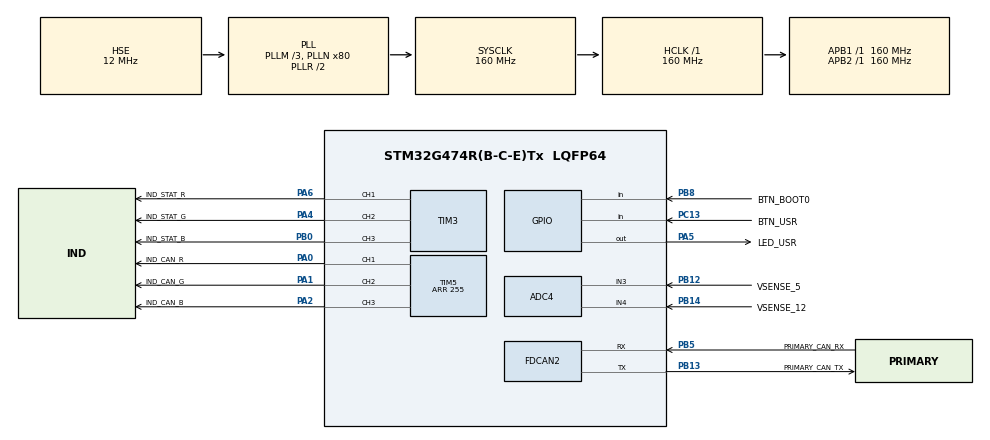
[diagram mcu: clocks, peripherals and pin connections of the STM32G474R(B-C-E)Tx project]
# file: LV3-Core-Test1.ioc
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ADC4.Channel-1\#ChannelRegularConversion=ADC_CHANNEL_3
ADC4.NbrOfConversionFlag=1
ADC4.OffsetNumber-1\#ChannelRegularConversion=ADC_OFFSET_NONE
ADC4.Rank-1\#ChannelRegularConversion=1
ADC4.SamplingTime-1\#ChannelRegularConversion=ADC_SAMPLETIME_2CYCLES_5
FDCAN2.CalculateBaudRateNominal=250000
FDCAN2.CalculateTimeBitNominal=4000
FDCAN2.CalculateTimeQuantumNominal=250.0
FDCAN2.NominalPrescaler=40
FDCAN2.NominalTimeSeg1=13
FDCAN2.NominalTimeSeg2=2
Mcu.Family=STM32G4
Mcu.Name=STM32G474R(B-C-E)Tx
Mcu.Package=LQFP64
NVIC.FDCAN2_IT0_IRQn=true\:0\:0\:false\:false\:true\:true\:true\:true
NVIC.FDCAN2_IT1_IRQn=true\:0\:0\:false\:false\:true\:true\:true\:true
NVIC.PriorityGroup=NVIC_PRIORITYGROUP_4
PA0.GPIO_Label=IND_CAN_R
PA0.Signal=S_TIM5_CH1
PA1.GPIO_Label=IND_CAN_G
PA1.Signal=S_TIM5_CH2
PA11.Signal=USB_DM
PA12.Signal=USB_DP
PA13.Mode=Trace_Asynchronous_SW
PA13.Signal=SYS_JTMS-SWDIO
PA14.Mode=Trace_Asynchronous_SW
PA14.Signal=SYS_JTCK-SWCLK
PA2.GPIO_Label=IND_CAN_B
PA2.Signal=S_TIM5_CH3
PA4.GPIO_Label=IND_STAT_G
PA4.Signal=S_TIM3_CH2
PA5.GPIO_Label=LED_USR
PA5.Signal=GPIO_Output
PA6.GPIO_Label=IND_STAT_R
PA6.Signal=S_TIM3_CH1
PA8.GPIO_Label=AUX_CAN_RX
PA8.Signal=FDCAN3_RX
PB0.GPIO_Label=IND_STAT_B
PB0.Signal=S_TIM3_CH3
PB12.GPIO_Label=VSENSE_5
PB12.Mode=IN3-Single-Ended
PB12.Signal=ADC4_IN3
PB13.GPIO_Label=PRIMARY_CAN_TX
PB13.Mode=FDCAN_Activate
PB13.Signal=FDCAN2_TX
PB14.GPIO_Label=VSENSE_12
PB14.Mode=IN4-Single-Ended
PB14.Signal=ADC4_IN4
PB3.Mode=Trace_Asynchronous_SW
PB3.Signal=SYS_JTDO-SWO
PB4.GPIO_Label=AUX_CAN_TX
PB4.Signal=FDCAN3_TX
PB5.GPIO_Label=PRIMARY_CAN_RX
PB5.Mode=FDCAN_Activate
PB5.Signal=FDCAN2_RX
PB8-BOOT0.GPIO_Label=BTN_BOOT0
PB8-BOOT0.Signal=GPIO_Input
PC13.GPIO_Label=BTN_USR
PC13.Signal=GPIO_Input
PF0-OSC_IN.Mode=HSE-External-Oscillator
PF0-OSC_IN.Signal=RCC_OSC_IN
PF1-OSC_OUT.Mode=HSE-External-Oscillator
PF1-OSC_OUT.Signal=RCC_OSC_OUT
ProjectManager.HeapSize=0x200
ProjectManager.StackSize=0x400
ProjectManager.TargetToolchain=CMake
RCC.ADC12Freq_Value=160000000
RCC.ADC345Freq_Value=160000000
RCC.AHBFreq_Value=160000000
RCC.APB1Freq_Value=160000000
RCC.APB1TimFreq_Value=160000000
RCC.APB2Freq_Value=160000000
RCC.APB2TimFreq_Value=160000000
RCC.CK48CLockSelection=RCC_USBCLKSOURCE_HSI48
RCC.CortexFreq_Value=160000000
RCC.EXTERNAL_CLOCK_VALUE=12288000
RCC.HCLKFreq_Value=160000000
RCC.HSE_VALUE=12000000
RCC.HSI48_VALUE=48000000
RCC.HSI_VALUE=16000000
RCC.LSE_VALUE=32768
RCC.PLLM=RCC_PLLM_DIV3
RCC.PLLN=80
RCC.PLLQ=RCC_PLLQ_DIV4
RCC.PLLSourceVirtual=RCC_PLLSOURCE_HSE
RCC.SYSCLKFreq_VALUE=160000000
RCC.SYSCLKSource=RCC_SYSCLKSOURCE_PLLCLK
RCC.USBFreq_Value=48000000
RCC.VCOOutputFreq_Value=320000000
SH.S_TIM3_CH1.0=TIM3_CH1,PWM Generation1 CH1
SH.S_TIM3_CH2.0=TIM3_CH2,PWM Generation2 CH2
SH.S_TIM3_CH3.0=TIM3_CH3,PWM Generation3 CH3
SH.S_TIM5_CH1.0=TIM5_CH1,PWM Generation1 CH1
SH.S_TIM5_CH2.0=TIM5_CH2,PWM Generation2 CH2
SH.S_TIM5_CH3.0=TIM5_CH3,PWM Generation3 CH3
TIM3.Channel-PWM\ Generation1\ CH1=TIM_CHANNEL_1
TIM3.Channel-PWM\ Generation2\ CH2=TIM_CHANNEL_2
TIM3.Channel-PWM\ Generation3\ CH3=TIM_CHANNEL_3
TIM5.Channel-PWM\ Generation1\ CH1=TIM_CHANNEL_1
TIM5.Channel-PWM\ Generation2\ CH2=TIM_CHANNEL_2
TIM5.Channel-PWM\ Generation3\ CH3=TIM_CHANNEL_3
TIM5.PeriodNoDither=255
VP_SYS_VS_DBSignals.Mode=DisableDeadBatterySignals
VP_TIM3_VS_ClockSourceINT.Mode=Internal
VP_TIM4_VS_ClockSourceINT.Mode=Internal
board=custom

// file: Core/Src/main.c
/* USER CODE BEGIN Header */
/**
 ******************************************************************************
 * @file           : main.c
 * @brief          : Main program body
 ******************************************************************************
 * @attention
 *
 * Copyright (c) 2026 STMicroelectronics.
 * All rights reserved.
 *
 * This software is licensed under terms that can be found in the LICENSE file
 * in the root directory of this software component.
 * If no LICENSE file comes with this software, it is provided AS-IS.
 *
 ******************************************************************************
 */
/* USER CODE END Header */
#include "main.h"

/* USER CODE BEGIN Includes */

#include "LV3_CAN.h"
#include "stm32g4xx_hal_fdcan.h"

/* USER CODE END Includes */

ADC_HandleTypeDef hadc4;

FDCAN_HandleTypeDef hfdcan2;

TIM_HandleTypeDef htim3;
TIM_HandleTypeDef htim4;
TIM_HandleTypeDef htim5;

void SystemClock_Config(void);
static void MX_GPIO_Init(void);
static void MX_TIM3_Init(void);
static void MX_TIM4_Init(void);
static void MX_ADC4_Init(void);
static void MX_FDCAN2_Init(void);
static void MX_TIM5_Init(void);

/* USER CODE BEGIN 0 */

uint32_t main_switch = 0;

const LV3_CAN_Binding lv3_can_bindings[] = {
    {&main_switch, SW_HV_MAIN, LV3_CAN_BindMode_Write}};

#define NUM_BINDINGS (sizeof(lv3_can_bindings) / sizeof(lv3_can_bindings[0]))

/* USER CODE END 0 */

int main(void) {

  /* MCU Configuration--------------------------------------------------------*/

  /* Reset of all peripherals, Initializes the Flash interface and the Systick.
   */
  HAL_Init();

  /* Configure the system clock */
  SystemClock_Config();

  /* Initialize all configured peripherals */
  MX_GPIO_Init();
  MX_TIM3_Init();
  MX_TIM4_Init();
  MX_ADC4_Init();
  MX_FDCAN2_Init();
  MX_TIM5_Init();
  /* USER CODE BEGIN 2 */

  LV3_CAN_Init(99, LV3_CAN_BusMode_Normal, lv3_can_bindings,
               sizeof(lv3_can_bindings) / sizeof(LV3_CAN_Binding));

  // LV3_CAN_ForceSend(sw)

  /* USER CODE END 2 */

  /* Infinite loop */
  while (1) {

    /* USER CODE BEGIN 3 */
    // read btn usr
    main_switch = HAL_GPIO_ReadPin(BTN_USR_GPIO_Port, BTN_USR_Pin);
    LV3_CAN_Loop();
  }
  /* USER CODE END 3 */
}

void SystemClock_Config(void) {
  RCC_OscInitTypeDef RCC_OscInitStruct = {0};
  RCC_ClkInitTypeDef RCC_ClkInitStruct = {0};

  /** Configure the main internal regulator output voltage
   */
  HAL_PWREx_ControlVoltageScaling(PWR_REGULATOR_VOLTAGE_SCALE1_BOOST);

  /** Initializes the RCC Oscillators according to the specified parameters
   * in the RCC_OscInitTypeDef structure.
   */
  RCC_OscInitStruct.OscillatorType = RCC_OSCILLATORTYPE_HSE;
  RCC_OscInitStruct.HSEState = RCC_HSE_ON;
  RCC_OscInitStruct.PLL.PLLState = RCC_PLL_ON;
  RCC_OscInitStruct.PLL.PLLSource = RCC_PLLSOURCE_HSE;
  RCC_OscInitStruct.PLL.PLLM = RCC_PLLM_DIV3;
  RCC_OscInitStruct.PLL.PLLN = 80;
  RCC_OscInitStruct.PLL.PLLP = RCC_PLLP_DIV2;
  RCC_OscInitStruct.PLL.PLLQ = RCC_PLLQ_DIV4;
  RCC_OscInitStruct.PLL.PLLR = RCC_PLLR_DIV2;
  if (HAL_RCC_OscConfig(&RCC_OscInitStruct) != HAL_OK) {
    Error_Handler();
  }

  /** Initializes the CPU, AHB and APB buses clocks
   */
  RCC_ClkInitStruct.ClockType = RCC_CLOCKTYPE_HCLK | RCC_CLOCKTYPE_SYSCLK |
                                RCC_CLOCKTYPE_PCLK1 | RCC_CLOCKTYPE_PCLK2;
  RCC_ClkInitStruct.SYSCLKSource = RCC_SYSCLKSOURCE_PLLCLK;
  RCC_ClkInitStruct.AHBCLKDivider = RCC_SYSCLK_DIV1;
  RCC_ClkInitStruct.APB1CLKDivider = RCC_HCLK_DIV1;
  RCC_ClkInitStruct.APB2CLKDivider = RCC_HCLK_DIV1;

  if (HAL_RCC_ClockConfig(&RCC_ClkInitStruct, FLASH_LATENCY_4) != HAL_OK) {
    Error_Handler();
  }
}

static void MX_ADC4_Init(void) {

  ADC_ChannelConfTypeDef sConfig = {0};

  /** Common config
   */
  hadc4.Instance = ADC4;
  hadc4.Init.ClockPrescaler = ADC_CLOCK_SYNC_PCLK_DIV4;
  hadc4.Init.Resolution = ADC_RESOLUTION_12B;
  hadc4.Init.DataAlign = ADC_DATAALIGN_RIGHT;
  hadc4.Init.GainCompensation = 0;
  hadc4.Init.ScanConvMode = ADC_SCAN_DISABLE;
  hadc4.Init.EOCSelection = ADC_EOC_SINGLE_CONV;
  hadc4.Init.LowPowerAutoWait = DISABLE;
  hadc4.Init.ContinuousConvMode = DISABLE;
  hadc4.Init.NbrOfConversion = 1;
  hadc4.Init.DiscontinuousConvMode = DISABLE;
  hadc4.Init.ExternalTrigConv = ADC_SOFTWARE_START;
  hadc4.Init.ExternalTrigConvEdge = ADC_EXTERNALTRIGCONVEDGE_NONE;
  hadc4.Init.DMAContinuousRequests = DISABLE;
  hadc4.Init.Overrun = ADC_OVR_DATA_PRESERVED;
  hadc4.Init.OversamplingMode = DISABLE;
  if (HAL_ADC_Init(&hadc4) != HAL_OK) {
    Error_Handler();
  }

  /** Configure Regular Channel
   */
  sConfig.Channel = ADC_CHANNEL_3;
  sConfig.Rank = ADC_REGULAR_RANK_1;
  sConfig.SamplingTime = ADC_SAMPLETIME_2CYCLES_5;
  sConfig.SingleDiff = ADC_SINGLE_ENDED;
  sConfig.OffsetNumber = ADC_OFFSET_NONE;
  sConfig.Offset = 0;
  if (HAL_ADC_ConfigChannel(&hadc4, &sConfig) != HAL_OK) {
    Error_Handler();
  }
}

static void MX_FDCAN2_Init(void) {

  hfdcan2.Instance = FDCAN2;
  hfdcan2.Init.ClockDivider = FDCAN_CLOCK_DIV1;
  hfdcan2.Init.FrameFormat = FDCAN_FRAME_CLASSIC;
  hfdcan2.Init.Mode = FDCAN_MODE_NORMAL;
  hfdcan2.Init.AutoRetransmission = DISABLE;
  hfdcan2.Init.TransmitPause = DISABLE;
  hfdcan2.Init.ProtocolException = DISABLE;
  hfdcan2.Init.NominalPrescaler = 40;
  hfdcan2.Init.NominalSyncJumpWidth = 1;
  hfdcan2.Init.NominalTimeSeg1 = 13;
  hfdcan2.Init.NominalTimeSeg2 = 2;
  hfdcan2.Init.DataPrescaler = 1;
  hfdcan2.Init.DataSyncJumpWidth = 1;
  hfdcan2.Init.DataTimeSeg1 = 1;
  hfdcan2.Init.DataTimeSeg2 = 1;
  hfdcan2.Init.StdFiltersNbr = 0;
  hfdcan2.Init.ExtFiltersNbr = 0;
  hfdcan2.Init.TxFifoQueueMode = FDCAN_TX_FIFO_OPERATION;
  if (HAL_FDCAN_Init(&hfdcan2) != HAL_OK) {
    Error_Handler();
  }
}

static void MX_TIM3_Init(void) {

  TIM_ClockConfigTypeDef sClockSourceConfig = {0};
  TIM_MasterConfigTypeDef sMasterConfig = {0};
  TIM_OC_InitTypeDef sConfigOC = {0};

  htim3.Instance = TIM3;
  htim3.Init.Prescaler = 0;
  htim3.Init.CounterMode = TIM_COUNTERMODE_UP;
  htim3.Init.Period = 65535;
  htim3.Init.ClockDivision = TIM_CLOCKDIVISION_DIV1;
  htim3.Init.AutoReloadPreload = TIM_AUTORELOAD_PRELOAD_DISABLE;
  if (HAL_TIM_Base_Init(&htim3) != HAL_OK) {
    Error_Handler();
  }
  sClockSourceConfig.ClockSource = TIM_CLOCKSOURCE_INTERNAL;
  if (HAL_TIM_ConfigClockSource(&htim3, &sClockSourceConfig) != HAL_OK) {
    Error_Handler();
  }
  if (HAL_TIM_PWM_Init(&htim3) != HAL_OK) {
    Error_Handler();
  }
  sMasterConfig.MasterOutputTrigger = TIM_TRGO_RESET;
  sMasterConfig.MasterSlaveMode = TIM_MASTERSLAVEMODE_DISABLE;
  if (HAL_TIMEx_MasterConfigSynchronization(&htim3, &sMasterConfig) != HAL_OK) {
    Error_Handler();
  }
  sConfigOC.OCMode = TIM_OCMODE_PWM1;
  sConfigOC.Pulse = 0;
  sConfigOC.OCPolarity = TIM_OCPOLARITY_HIGH;
  sConfigOC.OCFastMode = TIM_OCFAST_DISABLE;
  if (HAL_TIM_PWM_ConfigChannel(&htim3, &sConfigOC, TIM_CHANNEL_1) != HAL_OK) {
    Error_Handler();
  }
  if (HAL_TIM_PWM_ConfigChannel(&htim3, &sConfigOC, TIM_CHANNEL_2) != HAL_OK) {
    Error_Handler();
  }
  if (HAL_TIM_PWM_ConfigChannel(&htim3, &sConfigOC, TIM_CHANNEL_3) != HAL_OK) {
    Error_Handler();
  }
  HAL_TIM_MspPostInit(&htim3);
}

static void MX_TIM4_Init(void) {

  TIM_ClockConfigTypeDef sClockSourceConfig = {0};
  TIM_MasterConfigTypeDef sMasterConfig = {0};

  htim4.Instance = TIM4;
  htim4.Init.Prescaler = 0;
  htim4.Init.CounterMode = TIM_COUNTERMODE_UP;
  htim4.Init.Period = 65535;
  htim4.Init.ClockDivision = TIM_CLOCKDIVISION_DIV1;
  htim4.Init.AutoReloadPreload = TIM_AUTORELOAD_PRELOAD_DISABLE;
  if (HAL_TIM_Base_Init(&htim4) != HAL_OK) {
    Error_Handler();
  }
  sClockSourceConfig.ClockSource = TIM_CLOCKSOURCE_INTERNAL;
  if (HAL_TIM_ConfigClockSource(&htim4, &sClockSourceConfig) != HAL_OK) {
    Error_Handler();
  }
  sMasterConfig.MasterOutputTrigger = TIM_TRGO_RESET;
  sMasterConfig.MasterSlaveMode = TIM_MASTERSLAVEMODE_DISABLE;
  if (HAL_TIMEx_MasterConfigSynchronization(&htim4, &sMasterConfig) != HAL_OK) {
    Error_Handler();
  }
}

static void MX_TIM5_Init(void) {

  TIM_MasterConfigTypeDef sMasterConfig = {0};
  TIM_OC_InitTypeDef sConfigOC = {0};

  htim5.Instance = TIM5;
  htim5.Init.Prescaler = 0;
  htim5.Init.CounterMode = TIM_COUNTERMODE_UP;
  htim5.Init.Period = 255;
  htim5.Init.ClockDivision = TIM_CLOCKDIVISION_DIV1;
  htim5.Init.AutoReloadPreload = TIM_AUTORELOAD_PRELOAD_DISABLE;
  if (HAL_TIM_PWM_Init(&htim5) != HAL_OK) {
    Error_Handler();
  }
  sMasterConfig.MasterOutputTrigger = TIM_TRGO_RESET;
  sMasterConfig.MasterSlaveMode = TIM_MASTERSLAVEMODE_DISABLE;
  if (HAL_TIMEx_MasterConfigSynchronization(&htim5, &sMasterConfig) != HAL_OK) {
    Error_Handler();
  }
  sConfigOC.OCMode = TIM_OCMODE_PWM1;
  sConfigOC.Pulse = 0;
  sConfigOC.OCPolarity = TIM_OCPOLARITY_HIGH;
  sConfigOC.OCFastMode = TIM_OCFAST_DISABLE;
  if (HAL_TIM_PWM_ConfigChannel(&htim5, &sConfigOC, TIM_CHANNEL_1) != HAL_OK) {
    Error_Handler();
  }
  if (HAL_TIM_PWM_ConfigChannel(&htim5, &sConfigOC, TIM_CHANNEL_2) != HAL_OK) {
    Error_Handler();
  }
  if (HAL_TIM_PWM_ConfigChannel(&htim5, &sConfigOC, TIM_CHANNEL_3) != HAL_OK) {
    Error_Handler();
  }
  HAL_TIM_MspPostInit(&htim5);
}

static void MX_GPIO_Init(void) {
  GPIO_InitTypeDef GPIO_InitStruct = {0};

  /* GPIO Ports Clock Enable */
  __HAL_RCC_GPIOC_CLK_ENABLE();
  __HAL_RCC_GPIOF_CLK_ENABLE();
  __HAL_RCC_GPIOA_CLK_ENABLE();
  __HAL_RCC_GPIOB_CLK_ENABLE();

  /*Configure GPIO pin Output Level */
  HAL_GPIO_WritePin(LED_USR_GPIO_Port, LED_USR_Pin, GPIO_PIN_RESET);

  /*Configure GPIO pin : BTN_USR_Pin */
  GPIO_InitStruct.Pin = BTN_USR_Pin;
  GPIO_InitStruct.Mode = GPIO_MODE_INPUT;
  GPIO_InitStruct.Pull = GPIO_NOPULL;
  HAL_GPIO_Init(BTN_USR_GPIO_Port, &GPIO_InitStruct);

  /*Configure GPIO pin : LED_USR_Pin */
  GPIO_InitStruct.Pin = LED_USR_Pin;
  GPIO_InitStruct.Mode = GPIO_MODE_OUTPUT_PP;
  GPIO_InitStruct.Pull = GPIO_NOPULL;
  GPIO_InitStruct.Speed = GPIO_SPEED_FREQ_LOW;
  HAL_GPIO_Init(LED_USR_GPIO_Port, &GPIO_InitStruct);

  /*Configure GPIO pin : AUX_CAN_RX_Pin */
  GPIO_InitStruct.Pin = AUX_CAN_RX_Pin;
  GPIO_InitStruct.Mode = GPIO_MODE_AF_PP;
  GPIO_InitStruct.Pull = GPIO_NOPULL;
  GPIO_InitStruct.Speed = GPIO_SPEED_FREQ_LOW;
  GPIO_InitStruct.Alternate = GPIO_AF11_FDCAN3;
  HAL_GPIO_Init(AUX_CAN_RX_GPIO_Port, &GPIO_InitStruct);

  /*Configure GPIO pin : AUX_CAN_TX_Pin */
  GPIO_InitStruct.Pin = AUX_CAN_TX_Pin;
  GPIO_InitStruct.Mode = GPIO_MODE_AF_PP;
  GPIO_InitStruct.Pull = GPIO_NOPULL;
  GPIO_InitStruct.Speed = GPIO_SPEED_FREQ_LOW;
  GPIO_InitStruct.Alternate = GPIO_AF11_FDCAN3;
  HAL_GPIO_Init(AUX_CAN_TX_GPIO_Port, &GPIO_InitStruct);

  /*Configure GPIO pin : BTN_BOOT0_Pin */
  GPIO_InitStruct.Pin = BTN_BOOT0_Pin;
  GPIO_InitStruct.Mode = GPIO_MODE_INPUT;
  GPIO_InitStruct.Pull = GPIO_NOPULL;
  HAL_GPIO_Init(BTN_BOOT0_GPIO_Port, &GPIO_InitStruct);

}

void Error_Handler(void) {
  __disable_irq();
  while (1) {
  }
}
#ifdef USE_FULL_ASSERT
/**
 * @brief  Reports the name of the source file and the source line number
 *         where the assert_param error has occurred.
 * @param  file: pointer to the source file name
 * @param  line: assert_param error line source number
 * @retval None
 */
void assert_failed(uint8_t *file, uint32_t line) {
  /* USER CODE BEGIN 6 */
  /* User can add his own implementation to report the file name and line
     number, ex: printf("Wrong parameters value: file %s on line %d\r\n", file,
     line) */
  /* USER CODE END 6 */
}
#endif /* USE_FULL_ASSERT */
